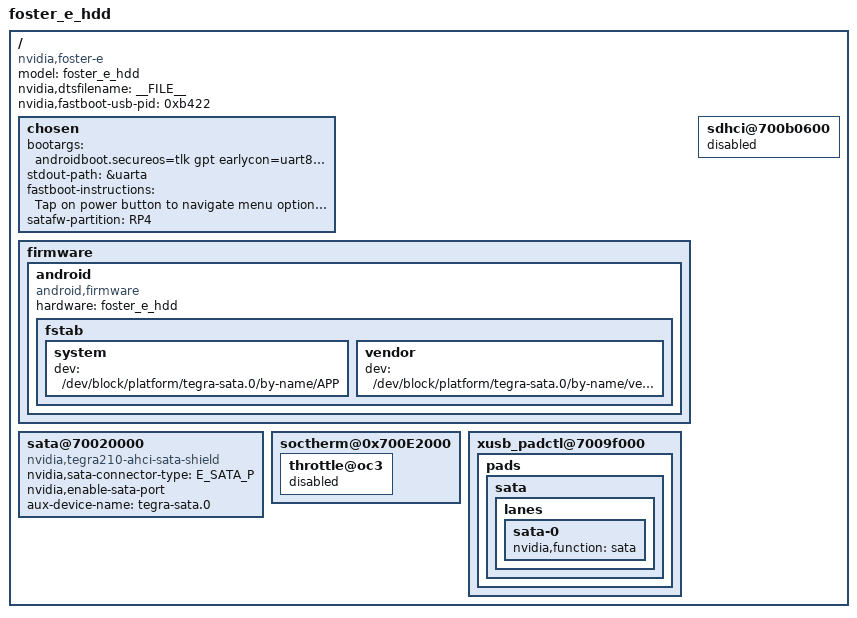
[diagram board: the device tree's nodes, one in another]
/*
 * arch/arm64/boot/dts/tegra210-foster-e-hdd-p2530-0932-e00-00.dts
 *
 * Copyright (c) 2014-2018, NVIDIA CORPORATION.  All rights reserved.
 *
 * This program is free software; you can redistribute it and/or modify
 * it under the terms of the GNU General Public License as published by
 * the Free Software Foundation; version 2 of the License.
 *
 * This program is distributed in the hope that it will be useful, but WITHOUT
 * ANY WARRANTY; without even the implied warranty of MERCHANTABILITY or
 * FITNESS FOR A PARTICULAR PURPOSE.  See the GNU General Public License for
 * more details.
 *
 * You should have received a copy of the GNU General Public License along
 * with this program; if not, write to the Free Software Foundation, Inc.,
 * 51 Franklin Street, Fifth Floor, Boston, MA  02110-1301, USA.
 *
 */
#include "tegra210-foster-e-p2530-common.dtsi"
#include <t210-common-platforms/tegra210-otg-gpio-detection-extcon.dtsi>
#include "foster-platforms/tegra210-loki-e-emc-a00.dtsi"
#include "foster-platforms/tegra210-foster-powermon-p2530-0930-e00.dtsi"

/ {
	model = "foster_e_hdd";
	compatible = "nvidia,foster-e", "nvidia,tegra210";
	nvidia,dtsfilename = __FILE__;
	nvidia,fastboot-usb-pid = <0xb422>;

	chosen {
		bootargs = "androidboot.secureos=tlk gpt earlycon=uart8250,mmio32,0x70006000";
		stdout-path = &uarta;
		fastboot-instructions = "Tap on power button to navigate menu options.\nHold down power button for 2 sec and release for selecting an option.\nOem unlock may take upto 2 hours.\n";
		satafw-partition = "RP4";
	};

	firmware {
		android {
			compatible = "android,firmware";
			hardware = "foster_e_hdd";
			fstab {
				system {
					dev = "/dev/block/platform/tegra-sata.0/by-name/APP";
				};
				vendor {
					dev = "/dev/block/platform/tegra-sata.0/by-name/vendor";
				};
			};
		};
	};

	sata@70020000 {
		status = "okay";
		compatible = "nvidia,tegra210-ahci-sata-shield";
		nvidia,sata-connector-type=<E_SATA_P>;
		nvidia,enable-sata-port;
		aux-device-name = "tegra-sata.0";
	};

	sdhci@700b0600 {
		status="disabled";
	};

	soctherm@0x700E2000 {
		throttle@oc3 {
			status = "disabled";
		};
	};

	xusb_padctl@7009f000 {
		status = "okay";
		pads {
			sata {
				status = "okay";
				lanes {
					sata-0 {
						nvidia,function = "sata";
						status = "okay";
					};
				};
			};
		};
	};
};
